# VPAC0_COMMON_0_IVPAC_TOP_0_CFG_SLV_HTS_S_VBUSP register map
Vendor: Texas Instruments
Peripheral module from a debugger description file (folder am62A).
Registers are 32-bit, read-write, reset 0x0 unless marked. A register's access mark holds for its fields unless they carry their own. Offsets are as the file gives them; lines under a group give offsets from that group; [hi:lo] are bit positions; {n}, {i} and the like mark numbered series; 'fields as' and 'values as' point back to an identical list; <NAME> marks a mode.

## VPAC0_COMMON_0_IVPAC_TOP_0_CFG_SLV_HTS_S_VBUSP (part 1 of 4)
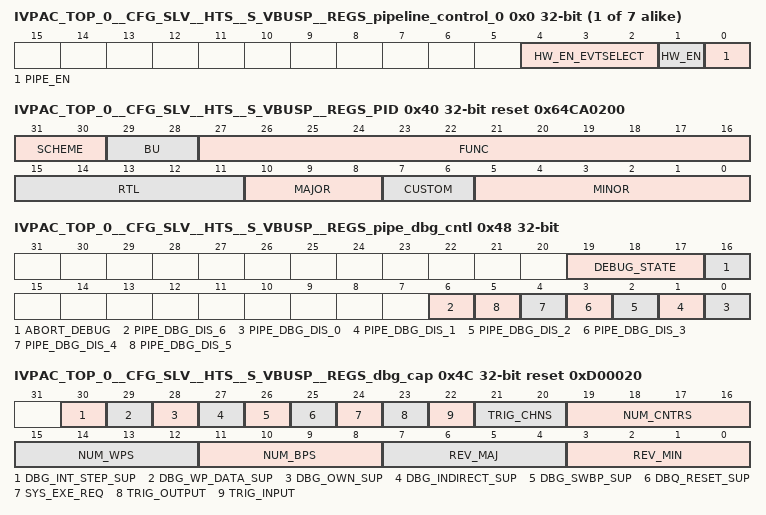
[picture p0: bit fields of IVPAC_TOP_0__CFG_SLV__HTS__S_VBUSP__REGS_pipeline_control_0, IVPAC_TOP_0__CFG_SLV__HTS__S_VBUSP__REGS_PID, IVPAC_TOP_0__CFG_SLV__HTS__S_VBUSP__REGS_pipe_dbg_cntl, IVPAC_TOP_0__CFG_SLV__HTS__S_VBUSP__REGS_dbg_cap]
{0x0+4i} IVPAC_TOP_0__CFG_SLV__HTS__S_VBUSP__REGS_pipeline_control_{i} (i=0..6) — Enable pipeline to activate all connected scheduler
  [4:2] HW_EN_EVTSELECT — Hw triggered pipeline enable on internally generated hts_event[hw_en_evtselect]
  [1] HW_EN — Hw event triggerred Pipeline {i} enable, '1': activate pipeline to receive hw event as described in hw_en_evtselect and hts_event_gen.evt_select , '0' : hw event based pipeline is not enabled
  [0] PIPE_EN — Pipeline {i} enable, writing '1' activate pipeline , writing '0' during active pipeline is illegal and behavior is undefined, read '1' -> pipeline is active , read '0' -> pipeline is inactive
0x40 IVPAC_TOP_0__CFG_SLV__HTS__S_VBUSP__REGS_PID ro reset 0x64CA0200 — HTS PID
  [31:30] SCHEME — Used to distinguish between old scheme and new scheme. Spare bit to encode future schemes
  [29:28] BU — BU indicator DSPS ==> 0x0 WTBU ==> 0x1 Processors ==> 0x2
  [27:16] FUNC — Function indicates a software compatible module family. If there is no level of software compatibility a new FUNC number, and hence PID, should be assigned.
  [15:11] RTL — RTL Version. R as described in PDR with additional clarifications and definitions below. Must be easily ECO-able or controlled during fabrication. Ideally through a top level metal mask or e-fuse. This number is maintained/owned by IP design owner. RTL follows a numbering such as X.Y.R.Z which are explained in this table. R changes ONLY when: (1) PDS uploads occur which may have been due to spec changes (2) Bug fixes occur (3) Resets to '0' when X or Y changes. Design team has an internal 'Z' (customer invisible) number which increments on every drop that happens due to DV and RTL updates. Z resets to 0 when R increments.
  [10:8] MAJOR — Major Revision. X as described in PDR with additional clarifications/definitions below. This number is owned/maintained by IP specification owner. X is part of IP numbering X.Y.R.Z. X changes ONLY when: (1) There is a major feature addition. An example would be adding Master Mode to Utopia Level2. The Func field (or Class/Type in old PID format) will remain the same. X does NOT change due to: (1) Bug fixes (2) Change in feature parameters.
  [7:6] CUSTOM — Indicates a special version for a particular device. Consequence of use may avoid use of standard Chip Support Library (CSL) / Drivers. 0 if non-custom.
  [5:0] MINOR — Minor Revision. Y as described in PDR with additional clarifications/definitions below. This number is owned/maintained by IP specification owner. Y changes ONLY when: (1) Features are scaled (up or down). Flexibility exists in that this feature scalability may either be represented in the Y change or a specific register in the IP that indicates which features are exactly available. (2) When feature creeps from Is-Not list to Is list. But this may not be the case once it sees silicon - in which case X will change. Y does NOT change due to: (1) Bug fixes (2) Typos or clarifications (3) major functional/feature change/addition/deletion. Instead these changes may be reflected via R, S, X as applicable. Spec owner maintains a customer-invisible number 'S' which changes due to: (1) Typos/clarifications (2) Bug documentation. Note that this bug is not due to a spec change but due to implementation. Nevertheless, the spec tracks the IP bugs. An RTL release (say for silicon PG1.1) that occurs due to bug fix should document the corresponding spec number (X.Y.S) in its release notes.
0x48 IVPAC_TOP_0__CFG_SLV__HTS__S_VBUSP__REGS_pipe_dbg_cntl access per field — Pipeline Debug Control register is used by debug software to control pipeline debug behavior
  [19:17] DEBUG_STATE ro — Current state of Debug activity
  [16] ABORT_DEBUG wo — '1' -> Abort Debug activity on debug enabled pipelines, '0' no impact
  [6] PIPE_DBG_DIS_6 rw — '1' -> Pipeline6 doesn't respond to debug events, '0' Pipeline5 respond to debug events
  [n] PIPE_DBG_DIS_{n} rw (n=0..5) — '1' -> Pipeline{n} doesn't respond to debug events, '0' Pipeline{n} respond to debug events
0x4C IVPAC_TOP_0__CFG_SLV__HTS__S_VBUSP__REGS_dbg_cap ro reset 0xD00020 — Debug Capability register is used by debug software to determine which optional debug modules are present and how many instances of each module exist.
  [30] DBG_INT_STEP_SUP — Indicates that debug execution control can determine if single step blocks or allows interrupts. b0 No step/interrupt control b1 Step interrupt control via DBG_INT_STEP_IN
  [29] DBG_WP_DATA_SUP — Indicates if the WP resources has corresponding data qualification. b0 - Not supported. b1 - Data qualifiers are supported.
  [28] DBG_OWN_SUP — Indicates if the HWA supports an module ownership. v2.0 and above. b0 - Not Supported. b1 - Ownership supported.
  [27] DBG_INDIRECT_SUP — Indicates if the HWA supports an indirect memory access port. v2.0 and above. b0 - Not Supported. b1 - Indirect port supported.
  [26] DBG_SWBP_SUP — Whether HWA Core supports SWBP or not. b0 - Not Supported. b1 - Supported.
  [25] DBQ_RESET_SUP — Whether HWA Core reset is supported or not which does not affect debug logic. b0 - Not Supported. b1 - Supported.
  [24] SYS_EXE_REQ — Whether HWA Core Execution status and control is supported. b0 - Not Supported. b1 - Supported.
  [23] TRIG_OUTPUT — b0 - Trigger Outputs are not supported. b1 - Trigger Outputs are supported.
  [22] TRIG_INPUT — b0 - Trigger Inputs are not supported. b1 - Trigger Inputs are supported.
  [21:20] TRIG_CHNS — Number of Trigger Channels Supported. b00 ------ No channels supported. b01 ------ One channel supported. b10 ------ Two channels supported. Others ---- Reserved.
  [19:16] NUM_CNTRS — The number of counter modules that exist. The registers supporting the counter modules must be implemented consecutively in the memory map.
  [15:12] NUM_WPS — The number of watchpoint modules that exist. The registers supporting the watchpoint modules must be implemented consecutively in the memory map
  [11:8] NUM_BPS — The number of breakpoint modules that exist. The registers supporting the breakpoint modules must be implemented consecutively in the memory map.
  [7:4] REV_MAJ — Major Revision
  [3:0] REV_MIN — Minor Revision
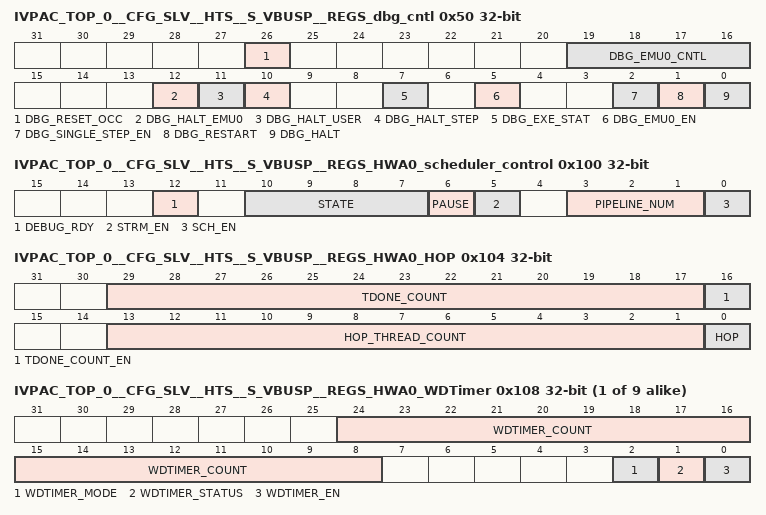
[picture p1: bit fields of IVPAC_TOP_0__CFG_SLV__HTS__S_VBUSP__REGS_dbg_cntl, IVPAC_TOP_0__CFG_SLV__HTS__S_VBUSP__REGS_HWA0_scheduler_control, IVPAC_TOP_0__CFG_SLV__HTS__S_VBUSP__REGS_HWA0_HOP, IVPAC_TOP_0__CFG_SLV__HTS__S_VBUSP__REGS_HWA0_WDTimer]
0x50 IVPAC_TOP_0__CFG_SLV__HTS__S_VBUSP__REGS_dbg_cntl access not given — Debug Control register is used by debug software to control all of the basic debug functions.
  [26] DBG_RESET_OCC — Sticky status bit to reflect reset has been generated (access R/W1TC)
  [19:16] DBG_EMU0_CNTL rw — EMU0 output control. The cross trigger output control. The value in this field determines the behavior of the outputs generated on EMU0. NOTE: The effect of setting any non-zero value is ignored if the HWA Core is currently in HALTED state until the HWA core exits and re-enters HALTED state. DBG_EMUn_CNTL Output Enable Output Pulse Description 0 De-asserted 0 NA No output. Input only 1 Stopping 0 Yes Pulse on halt. If this bit is set when halted then no effect until the HWA re-enters halted state. 2 HWBP 0 Yes Pulse when any HWBP triggers 3 HWWP 0 Yes Pulse when any HWWP triggers 4 Asserted 1 No Drive pin high 5 Asserted 0 No Drive pin low 6-15 - - Reserved
  [12] DBG_HALT_EMU0 ro — Execution halted due to trigger in on EMU0 input Set to '1' when halt due to EMU0 input completes Set to '0' when execution resumes
  [11] DBG_HALT_USER ro — Execution halted due to register update of DBG_HALT Set to '1' when halt due to DBG_HALT update completes Set to '0' when execution resumes
  [10] DBG_HALT_STEP ro — Execution halted due to single step completion Set to '1' when the single step completes Set to '0' when execution resumes
  [7] DBG_EXE_STAT ro — The execution status of the module Set to '1' when halted due to debug event Set to '0' when execution resumes
  [5] DBG_EMU0_EN rw — EMU0 input trigger enable Writing '1' enables halting on the falling edge of the EMU0 input Writing '0' disables halts via EMU0 input
  [2] DBG_SINGLE_STEP_EN rw — Single Step Execution enable. When this bit is set, the accelerator core shall be halted upon execution of a single instruction. This is after the accelerator core has left the halted state by clearing the DBG_HALT control bit. Writing '1' enables halting when the next instruction following exit from halted state is executed. Writing '0' disables halts via single step. NOTE: 1. When the accelerator core enters its natural execution state, it may or may not execute an instruction and re-enter HALTED state.
  [1] DBG_RESTART rw — Debug Restart Status bit.This bit is normally set when the DBG_HALT bit transitions from '1' to '0' when the natural execution state is entered.It is a sticky bit. It may also be set when a synchronous run causes the accelerator to leave halted state. Reading '1' means HWA Core exited halted state (at least temporarily). Reading '0' means HWA Core did not exit halted state. Writing '1' shall clear the bit if set. There is no restriction on when it can be cleared. Writing '0' shall have no effect.
  [0] DBG_HALT rw — Global debug run control. The bit will be read as being set upon entry to HALTED state due to halted state being entered because of SWBP, HWBP, HWWP, EMU0 / 1 trigger or manual halt requested through this control. Writing '1' when read '0' shall cause a halt on the next possible halt boundary.Writing '0' when read '1' returns the system to the natural execution state.A synchronous run hardware request has the same effect.Reading '1' means that the halted state has been reached or been requested by the manual halt mechanism.Reading '0' means that the target is in its natural execution state.NOTE: 1. The natural execution state means the FSM state entered prior to last entry into Halted state. 2. This would be the last application requested FSM state unless the DBG_SYS_EXE_REQ control was used to change it.
{0x54+4i} IVPAC_TOP_0__CFG_SLV__HTS__S_VBUSP__REGS_hts_event_gen{i} (i=0..7) — select one of internal hts_event of width 34 out of 3'b0,pipeline_eop[6:0],1'b0,start_frame_evt,2'b0,hwa_eop[8:0],2'b0,hwa_init[8:0] bus as hts_event{i}
  [5:0] EVT_SELECT — internal hts_event index for hts_event_gen{i}
0x100 IVPAC_TOP_0__CFG_SLV__HTS__S_VBUSP__REGS_HWA0_scheduler_control access per field — Scheduler Control Register
  [12] DEBUG_RDY rw — '0' -> HWA0 Scheduler resources must not be read during halted state. '1'-> HWA0 Scheduler resources are readable during halted state
  [10:7] STATE ro — Current state of HWA0 Scheduler
  [6] PAUSE rw — '1' -> pause/suspend scheduler , '0' -> resume scheduler
  [5] STRM_EN rw — '1' -> Streaming input enable, '0' No streaming input
  [3:1] PIPELINE_NUM rw — Pipeline Number of HWA0 Scheduler
  [0] SCH_EN rw — scheduler enable; write '1' to enable scheduler
0x104 IVPAC_TOP_0__CFG_SLV__HTS__S_VBUSP__REGS_HWA0_HOP access per field — Scheduler HOP Control Register. Help in detecting eop within scheduler. Once configured, it counts task/channel starts and stops issuing further start. Specifically useful for Head of pipe dma scheduler .
  [29:17] TDONE_COUNT ro — current tdone count value
  [16] TDONE_COUNT_EN rw — '1' -> Count tdone(Not impacted due to individual channel mask). Current tdone count available as read value. when enabled, it triggers tdone_intr when (tdone_count==hop_thread_count) '0' -> No count ; Note that tdone_count value is available as read value when hop=1 as well.
  [13:1] HOP_THREAD_COUNT rw — Number of Task count for Head of pipe
  [0] HOP rw — '1' -> Head of Pipe producer Sch , '0' -> No hop
{0x108+0x260*i} IVPAC_TOP_0__CFG_SLV__HTS__S_VBUSP__REGS_HWA{i}_WDTimer access per field (i=0..8) — Watchdog timer control register
  [24:8] WDTIMER_COUNT ro — Current value of HWA{i} Scheduler watchdog timer count
  [2] WDTIMER_MODE rw — Watchdog timeout count '1' -> 128K , '0' -> 64K
  [1] WDTIMER_STATUS ro — HWA{i} Scheduler watchdog timer status '1' -> Timer Active '0' -> Timer Inactive (count is stable)
  [0] WDTIMER_EN rw — '1' -> activate watchdog timer for 64K VPAC/DMPAC cycles between task start and task done '0' -> Disable watchdog timer
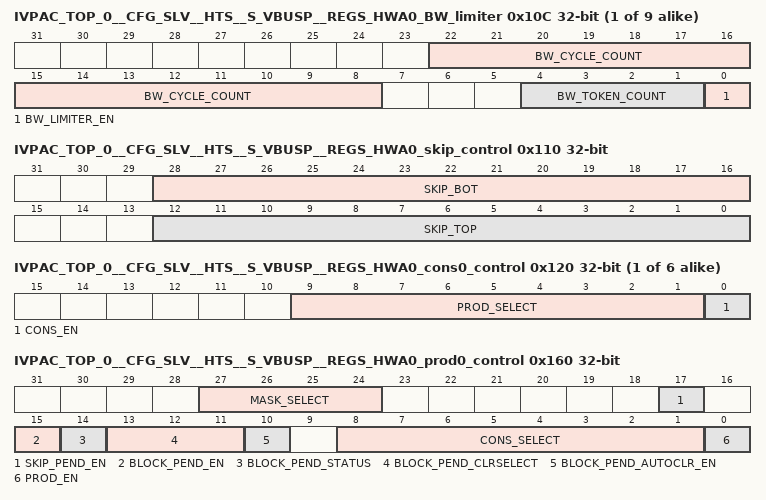
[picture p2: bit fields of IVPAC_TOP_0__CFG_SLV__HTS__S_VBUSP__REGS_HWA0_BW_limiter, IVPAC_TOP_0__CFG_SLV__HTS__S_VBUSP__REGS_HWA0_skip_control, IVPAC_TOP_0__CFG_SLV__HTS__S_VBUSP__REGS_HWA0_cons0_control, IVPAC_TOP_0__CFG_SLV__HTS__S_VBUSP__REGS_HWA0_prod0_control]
{0x10C+0x260*i} IVPAC_TOP_0__CFG_SLV__HTS__S_VBUSP__REGS_HWA{i}_BW_limiter (i=0..8) — Scheduler BW Control Register. Processing unit level BW control. Use DMA to eliminate peak system BW within processing units line/Block
  [22:8] BW_CYCLE_COUNT — Average Cycle count between successive Task Start
  [4:1] BW_TOKEN_COUNT — Max Token count to create average BW
  [0] BW_LIMITER_EN — '1' -> Enable BW limiter function for HWA{i} sch, '0' --> Disable
0x110 IVPAC_TOP_0__CFG_SLV__HTS__S_VBUSP__REGS_HWA0_skip_control — Scheduler Skip Control Register. If enabled in specific prod socket, tdones within skip_top and skip_bot is included in pend generation. tdone_count_en bit in HOP needs to be set to use SKIP feature.
  [28:16] SKIP_BOT — skip/ignore tdone from tdone_count=skip_bot till eop in HWA0 scheduler skip-enabled prod socket
  [12:0] SKIP_TOP — skip/ignore tdone from tdone_count=0 till tdone_count=skip_top value in HWA0 scheduler skip-enabled prod socket
{0x120+8i} IVPAC_TOP_0__CFG_SLV__HTS__S_VBUSP__REGS_HWA0_cons{i}_control (i=0..5) — Controlling consumer socket {i} for HWA0
  [9:1] PROD_SELECT — producer select for HWA0 cons socket {i}
  [0] CONS_EN — '1' -> Consumer socket {i} enable , '0' Disable
0x160 IVPAC_TOP_0__CFG_SLV__HTS__S_VBUSP__REGS_HWA0_prod0_control — Controlling producer socket0 for HWA0
  [27:24] MASK_SELECT — define which tdone_mask apply to prod socket 0. tdone_mask[mask_select] applies to prod_socket0. Valid value in range 0 - 6
  [17] SKIP_PEND_EN — '1' -> Producer socket 0 skip enable , '0' Disable
  [15] BLOCK_PEND_EN — '1' -> block pend at the end of hwa eop enabled at Producer socket 0 , '0' Disable
  [14] BLOCK_PEND_STATUS — '1' -> block pend status at Producer socket 0 , '0' Disable
  [13:11] BLOCK_PEND_CLRSELECT — hts_event_gen[block_pend_clrselect] will be used to clear blocked pend in super pipeline
  [10] BLOCK_PEND_AUTOCLR_EN — '1' -> Enable clearing block pend status at Producer socket 0 by hts_event_gen[block_pend_clrselect], '0' Disable
  [8:1] CONS_SELECT — consumer select for HWA0 prod socket 0. Used in decrementing count of producer buffer
  [0] PROD_EN — '1' -> Producer socket 0 enable , '0' Disable
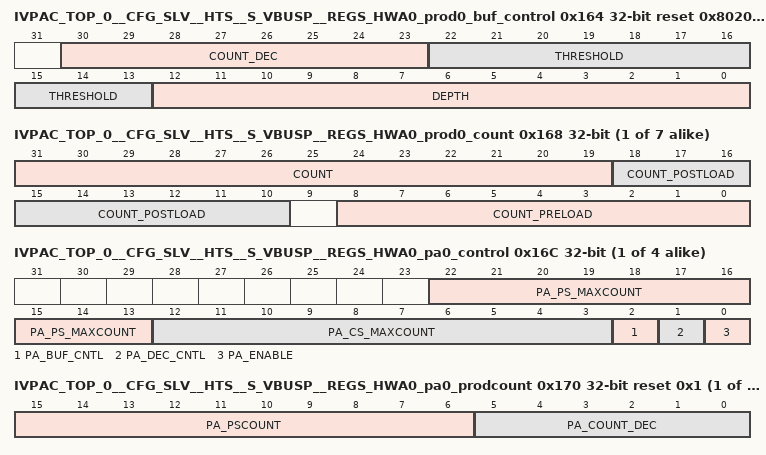
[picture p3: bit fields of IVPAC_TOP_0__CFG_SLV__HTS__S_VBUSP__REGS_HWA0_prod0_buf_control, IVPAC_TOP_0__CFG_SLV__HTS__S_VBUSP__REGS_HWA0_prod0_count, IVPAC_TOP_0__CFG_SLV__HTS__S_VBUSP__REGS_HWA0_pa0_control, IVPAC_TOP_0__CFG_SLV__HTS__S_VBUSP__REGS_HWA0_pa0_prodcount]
{0x164+0x20*i} IVPAC_TOP_0__CFG_SLV__HTS__S_VBUSP__REGS_HWA0_prod{i}_buf_control reset 0x802000 (i=0..6) — Controlling producer socket{i} buffer for HWA0
  [30:23] COUNT_DEC — Count decrement value for prod count
  [22:13] THRESHOLD — Count threshold to generate pend for consumer
  [12:0] DEPTH — Maximum number of producer buffer count
{0x168+0x20*i} IVPAC_TOP_0__CFG_SLV__HTS__S_VBUSP__REGS_HWA0_prod{i}_count access per field (i=0..6) — Defining count values for pre/post load for generating pend by HWA0 prod{i}
  [31:19] COUNT ro — current count value
  [18:10] COUNT_POSTLOAD rw — count postload after producer max thread count reached
  [8:0] COUNT_PRELOAD rw — count preload after scheduler start/init
{0x16C+0x20*i} IVPAC_TOP_0__CFG_SLV__HTS__S_VBUSP__REGS_HWA0_pa{i}_control (i=0..3) — control register to manage pattern adapter on HWA0 prod socket{i}
  [22:13] PA_PS_MAXCOUNT — destination count for pattern adaptation (N), M --> N
  [12:3] PA_CS_MAXCOUNT — source count for pattern adaptation (M), M --> N
  [2] PA_BUF_CNTL — '1' -> Apply threshold, count_preload and count_postload on pattern adapter count (use this only when pa_enable='1') '0' -> Apply threshold, count_preload and count_postload on prod count (same behavior as if no pattern adapter. Note when pa_enable='1' and pa_buf_cntl='0' threshold is not used and ignored)
  [1] PA_DEC_CNTL — '1' -> post pattern adaptation, decrement ps count by count_dec , '0' -> post pattern adaptation, decrement ps count by pa_cs_maxcount
  [0] PA_ENABLE — '1' -> pa enable, '0' -> disable
{0x170+0x20*i} IVPAC_TOP_0__CFG_SLV__HTS__S_VBUSP__REGS_HWA0_pa{i}_prodcount access per field reset 0x1 (i=0..3) — count values for HWA0 prod socket{i}
  [15:6] PA_PSCOUNT ro — current count value of pa prod count
  [5:0] PA_COUNT_DEC rw — Decrement count value of pa_prod_count after pattern adapter prod count reaches threshold
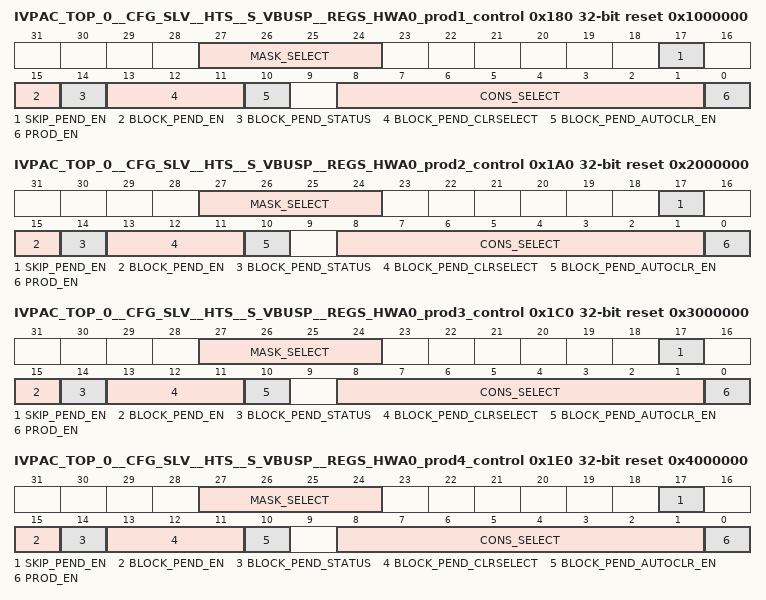
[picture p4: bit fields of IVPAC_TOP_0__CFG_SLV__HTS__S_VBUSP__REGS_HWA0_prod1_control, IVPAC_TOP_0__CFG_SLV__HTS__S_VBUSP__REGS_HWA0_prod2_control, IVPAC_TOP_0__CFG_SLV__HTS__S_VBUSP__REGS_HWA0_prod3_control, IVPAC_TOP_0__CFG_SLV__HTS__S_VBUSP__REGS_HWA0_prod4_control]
0x180 IVPAC_TOP_0__CFG_SLV__HTS__S_VBUSP__REGS_HWA0_prod1_control reset 0x1000000 — Controlling producer socket1 for HWA0
  [27:24] MASK_SELECT — define which tdone_mask apply to prod socket 1. tdone_mask[mask_select] applies to prod_socket1. Valid value in range 0 - 6
  [17] SKIP_PEND_EN — '1' -> Producer socket 1 skip enable , '0' Disable
  [15] BLOCK_PEND_EN — '1' -> block pend at the end of hwa eop enabled at Producer socket 1 , '0' Disable
  [14] BLOCK_PEND_STATUS — '1' -> block pend status at Producer socket 1 , '0' Disable
  [13:11] BLOCK_PEND_CLRSELECT — hts_event_gen[block_pend_clrselect] will be used to clear blocked pend in super pipeline
  [10] BLOCK_PEND_AUTOCLR_EN — '1' -> Enable clearing block pend status at Producer socket 1 by hts_event_gen[block_pend_clrselect], '0' Disable
  [8:1] CONS_SELECT — consumer select for HWA0 prod socket 1. Used in decrementing count of producer buffer
  [0] PROD_EN — '1' -> Producer socket 1 enable , '0' Disable
0x1A0 IVPAC_TOP_0__CFG_SLV__HTS__S_VBUSP__REGS_HWA0_prod2_control reset 0x2000000 — Controlling producer socket2 for HWA0
  [27:24] MASK_SELECT — define which tdone_mask apply to prod socket 2. tdone_mask[mask_select] applies to prod_socket2. Valid value in range 0 - 6
  [17] SKIP_PEND_EN — '1' -> Producer socket 2 skip enable , '0' Disable
  [15] BLOCK_PEND_EN — '1' -> block pend at the end of hwa eop enabled at Producer socket 2 , '0' Disable
  [14] BLOCK_PEND_STATUS — '1' -> block pend status at Producer socket 2 , '0' Disable
  [13:11] BLOCK_PEND_CLRSELECT — hts_event_gen[block_pend_clrselect] will be used to clear blocked pend in super pipeline
  [10] BLOCK_PEND_AUTOCLR_EN — '1' -> Enable clearing block pend status at Producer socket 2 by hts_event_gen[block_pend_clrselect], '0' Disable
  [8:1] CONS_SELECT — consumer select for HWA0 prod socket 2. Used in decrementing count of producer buffer
  [0] PROD_EN — '1' -> Producer socket 2 enable , '0' Disable
0x1C0 IVPAC_TOP_0__CFG_SLV__HTS__S_VBUSP__REGS_HWA0_prod3_control reset 0x3000000 — Controlling producer socket3 for HWA0
  [27:24] MASK_SELECT — define which tdone_mask apply to prod socket 3. tdone_mask[mask_select] applies to prod_socket3. Valid value in range 0 - 6
  [17] SKIP_PEND_EN — '1' -> Producer socket 3 skip enable , '0' Disable
  [15] BLOCK_PEND_EN — '1' -> block pend at the end of hwa eop enabled at Producer socket 3 , '0' Disable
  [14] BLOCK_PEND_STATUS — '1' -> block pend status at Producer socket 3 , '0' Disable
  [13:11] BLOCK_PEND_CLRSELECT — hts_event_gen[block_pend_clrselect] will be used to clear blocked pend in super pipeline
  [10] BLOCK_PEND_AUTOCLR_EN — '1' -> Enable clearing block pend status at Producer socket 3 by hts_event_gen[block_pend_clrselect], '0' Disable
  [8:1] CONS_SELECT — consumer select for HWA0 prod socket 3. Used in decrementing count of producer buffer
  [0] PROD_EN — '1' -> Producer socket 3 enable , '0' Disable
0x1E0 IVPAC_TOP_0__CFG_SLV__HTS__S_VBUSP__REGS_HWA0_prod4_control reset 0x4000000 — Controlling producer socket4 for HWA0
  [27:24] MASK_SELECT — define which tdone_mask apply to prod socket 4. tdone_mask[mask_select] applies to prod_socket4. Valid value in range 0 - 6
  [17] SKIP_PEND_EN — '1' -> Producer socket 4 skip enable , '0' Disable
  [15] BLOCK_PEND_EN — '1' -> block pend at the end of hwa eop enabled at Producer socket 4 , '0' Disable
  [14] BLOCK_PEND_STATUS — '1' -> block pend status at Producer socket 4 , '0' Disable
  [13:11] BLOCK_PEND_CLRSELECT — hts_event_gen[block_pend_clrselect] will be used to clear blocked pend in super pipeline
  [10] BLOCK_PEND_AUTOCLR_EN — '1' -> Enable clearing block pend status at Producer socket 4 by hts_event_gen[block_pend_clrselect], '0' Disable
  [8:1] CONS_SELECT — consumer select for HWA0 prod socket 4. Used in decrementing count of producer buffer
  [0] PROD_EN — '1' -> Producer socket 4 enable , '0' Disable
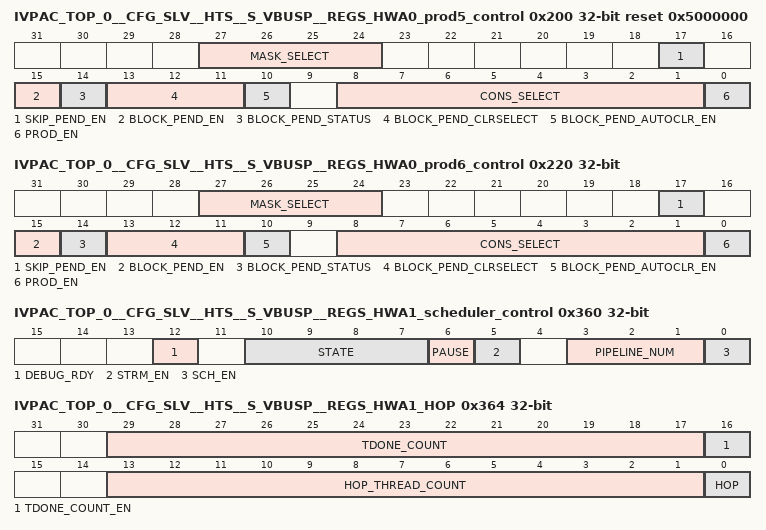
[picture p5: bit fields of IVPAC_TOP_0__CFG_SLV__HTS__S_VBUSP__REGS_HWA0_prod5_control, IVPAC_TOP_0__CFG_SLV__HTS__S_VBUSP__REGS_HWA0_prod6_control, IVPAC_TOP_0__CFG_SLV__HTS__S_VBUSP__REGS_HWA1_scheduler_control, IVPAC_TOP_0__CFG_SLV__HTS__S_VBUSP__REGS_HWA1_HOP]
0x200 IVPAC_TOP_0__CFG_SLV__HTS__S_VBUSP__REGS_HWA0_prod5_control reset 0x5000000 — Controlling producer socket5 for HWA0
  [27:24] MASK_SELECT — define which tdone_mask apply to prod socket 5. tdone_mask[mask_select] applies to prod_socket5. Valid value in range 0 - 6
  [17] SKIP_PEND_EN — '1' -> Producer socket 5 skip enable , '0' Disable
  [15] BLOCK_PEND_EN — '1' -> block pend at the end of hwa eop enabled at Producer socket 5 , '0' Disable
  [14] BLOCK_PEND_STATUS — '1' -> block pend status at Producer socket 5 , '0' Disable
  [13:11] BLOCK_PEND_CLRSELECT — hts_event_gen[block_pend_clrselect] will be used to clear blocked pend in super pipeline
  [10] BLOCK_PEND_AUTOCLR_EN — '1' -> Enable clearing block pend status at Producer socket 5 by hts_event_gen[block_pend_clrselect], '0' Disable
  [8:1] CONS_SELECT — consumer select for HWA0 prod socket 5. Used in decrementing count of producer buffer
  [0] PROD_EN — '1' -> Producer socket 5 enable , '0' Disable
0x220 IVPAC_TOP_0__CFG_SLV__HTS__S_VBUSP__REGS_HWA0_prod6_control — Controlling producer socket6 for HWA0
  [27:24] MASK_SELECT — define which tdone_mask apply to prod socket 6. tdone_mask[mask_select] applies to prod_socket6. Valid value in range 0 - 6
  [17] SKIP_PEND_EN — '1' -> Producer socket 6 skip enable , '0' Disable
  [15] BLOCK_PEND_EN — '1' -> block pend at the end of hwa eop enabled at Producer socket 6 , '0' Disable
  [14] BLOCK_PEND_STATUS — '1' -> block pend status at Producer socket 6 , '0' Disable
  [13:11] BLOCK_PEND_CLRSELECT — hts_event_gen[block_pend_clrselect] will be used to clear blocked pend in super pipeline
  [10] BLOCK_PEND_AUTOCLR_EN — '1' -> Enable clearing block pend status at Producer socket 6 by hts_event_gen[block_pend_clrselect], '0' Disable
  [8:1] CONS_SELECT — consumer select for HWA0 prod socket 6. Used in decrementing count of producer buffer
  [0] PROD_EN — '1' -> Producer socket 6 enable , '0' Disable
0x360 IVPAC_TOP_0__CFG_SLV__HTS__S_VBUSP__REGS_HWA1_scheduler_control access per field — Scheduler Control Register
  [12] DEBUG_RDY rw — '0' -> HWA1 Scheduler resources must not be read during halted state. '1'-> HWA1 Scheduler resources are readable during halted state
  [10:7] STATE ro — Current state of HWA1 Scheduler
  [6] PAUSE rw — '1' -> pause/suspend scheduler , '0' -> resume scheduler
  [5] STRM_EN rw — '1' -> Streaming input enable, '0' No streaming input
  [3:1] PIPELINE_NUM rw — Pipeline Number of HWA1 Scheduler
  [0] SCH_EN rw — scheduler enable; write '1' to enable scheduler
0x364 IVPAC_TOP_0__CFG_SLV__HTS__S_VBUSP__REGS_HWA1_HOP access per field — Scheduler HOP Control Register. Help in detecting eop within scheduler. Once configured, it counts task/channel starts and stops issuing further start. Specifically useful for Head of pipe dma scheduler .
  fields as IVPAC_TOP_0__CFG_SLV__HTS__S_VBUSP__REGS_HWA0_HOP
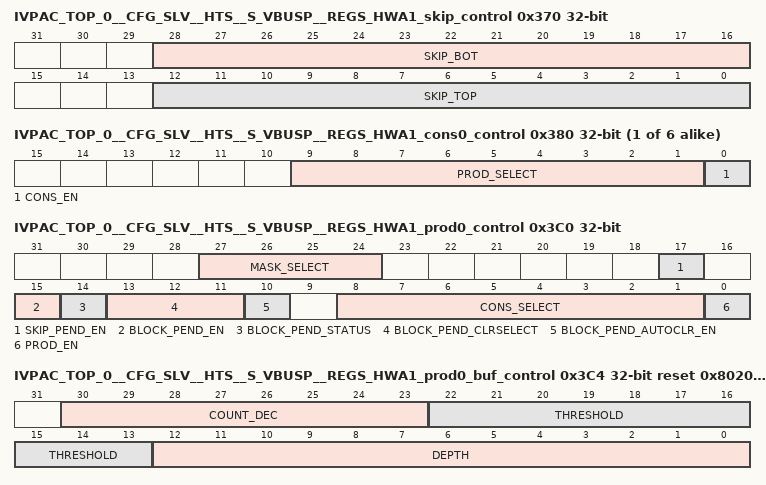
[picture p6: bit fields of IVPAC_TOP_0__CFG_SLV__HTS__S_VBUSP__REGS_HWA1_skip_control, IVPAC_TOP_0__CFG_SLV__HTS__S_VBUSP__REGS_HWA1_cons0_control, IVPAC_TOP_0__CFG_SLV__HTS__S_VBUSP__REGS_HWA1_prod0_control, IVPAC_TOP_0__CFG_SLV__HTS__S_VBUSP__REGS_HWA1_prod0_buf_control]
0x370 IVPAC_TOP_0__CFG_SLV__HTS__S_VBUSP__REGS_HWA1_skip_control — Scheduler Skip Control Register. If enabled in specific prod socket, tdones within skip_top and skip_bot is included in pend generation. tdone_count_en bit in HOP needs to be set to use SKIP feature.
  [28:16] SKIP_BOT — skip/ignore tdone from tdone_count=skip_bot till eop in HWA1 scheduler skip-enabled prod socket
  [12:0] SKIP_TOP — skip/ignore tdone from tdone_count=0 till tdone_count=skip_top value in HWA1 scheduler skip-enabled prod socket
{0x380+8i} IVPAC_TOP_0__CFG_SLV__HTS__S_VBUSP__REGS_HWA1_cons{i}_control (i=0..5) — Controlling consumer socket {i} for HWA1
  [9:1] PROD_SELECT — producer select for HWA1 cons socket {i}
  [0] CONS_EN — '1' -> Consumer socket {i} enable , '0' Disable
0x3C0 IVPAC_TOP_0__CFG_SLV__HTS__S_VBUSP__REGS_HWA1_prod0_control — Controlling producer socket0 for HWA1
  [27:24] MASK_SELECT — define which tdone_mask apply to prod socket 0. tdone_mask[mask_select] applies to prod_socket0. Valid value in range 0 - 6
  [17] SKIP_PEND_EN — '1' -> Producer socket 0 skip enable , '0' Disable
  [15] BLOCK_PEND_EN — '1' -> block pend at the end of hwa eop enabled at Producer socket 0 , '0' Disable
  [14] BLOCK_PEND_STATUS — '1' -> block pend status at Producer socket 0 , '0' Disable
  [13:11] BLOCK_PEND_CLRSELECT — hts_event_gen[block_pend_clrselect] will be used to clear blocked pend in super pipeline
  [10] BLOCK_PEND_AUTOCLR_EN — '1' -> Enable clearing block pend status at Producer socket 0 by hts_event_gen[block_pend_clrselect], '0' Disable
  [8:1] CONS_SELECT — consumer select for HWA1 prod socket 0. Used in decrementing count of producer buffer
  [0] PROD_EN — '1' -> Producer socket 0 enable , '0' Disable
{0x3C4+0x20*i} IVPAC_TOP_0__CFG_SLV__HTS__S_VBUSP__REGS_HWA1_prod{i}_buf_control reset 0x802000 (i=0..6) — Controlling producer socket{i} buffer for HWA1
  fields as IVPAC_TOP_0__CFG_SLV__HTS__S_VBUSP__REGS_HWA0_prod0_buf_control
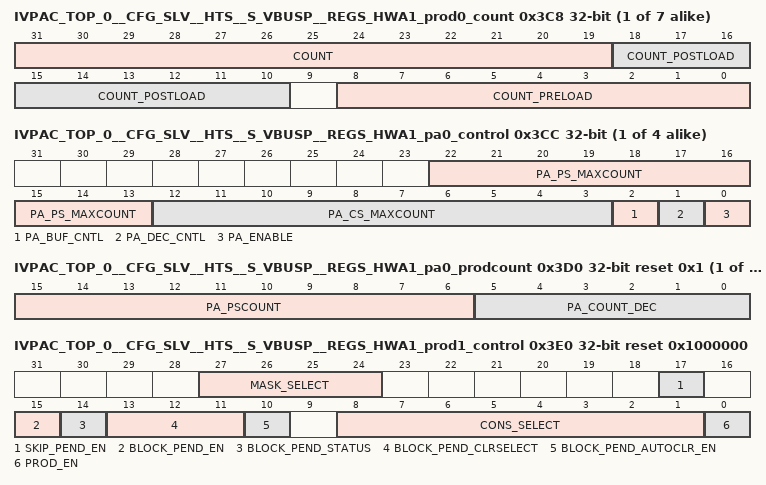
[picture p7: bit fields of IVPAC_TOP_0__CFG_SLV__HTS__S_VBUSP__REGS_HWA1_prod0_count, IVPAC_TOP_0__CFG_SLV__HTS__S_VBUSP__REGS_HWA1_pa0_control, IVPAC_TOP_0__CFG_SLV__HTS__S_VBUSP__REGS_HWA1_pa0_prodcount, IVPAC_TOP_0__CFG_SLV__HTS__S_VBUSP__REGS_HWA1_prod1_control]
{0x3C8+0x20*i} IVPAC_TOP_0__CFG_SLV__HTS__S_VBUSP__REGS_HWA1_prod{i}_count access per field (i=0..6) — Defining count values for pre/post load for generating pend by HWA1 prod{i}
  fields as IVPAC_TOP_0__CFG_SLV__HTS__S_VBUSP__REGS_HWA0_prod0_count
{0x3CC+0x20*i} IVPAC_TOP_0__CFG_SLV__HTS__S_VBUSP__REGS_HWA1_pa{i}_control (i=0..3) — control register to manage pattern adapter on HWA1 prod socket{i}
  fields as IVPAC_TOP_0__CFG_SLV__HTS__S_VBUSP__REGS_HWA0_pa0_control
{0x3D0+0x20*i} IVPAC_TOP_0__CFG_SLV__HTS__S_VBUSP__REGS_HWA1_pa{i}_prodcount access per field reset 0x1 (i=0..3) — count values for HWA1 prod socket{i}
  fields as IVPAC_TOP_0__CFG_SLV__HTS__S_VBUSP__REGS_HWA0_pa0_prodcount
0x3E0 IVPAC_TOP_0__CFG_SLV__HTS__S_VBUSP__REGS_HWA1_prod1_control reset 0x1000000 — Controlling producer socket1 for HWA1
  [27:24] MASK_SELECT — define which tdone_mask apply to prod socket 1. tdone_mask[mask_select] applies to prod_socket1. Valid value in range 0 - 6
  [17] SKIP_PEND_EN — '1' -> Producer socket 1 skip enable , '0' Disable
  [15] BLOCK_PEND_EN — '1' -> block pend at the end of hwa eop enabled at Producer socket 1 , '0' Disable
  [14] BLOCK_PEND_STATUS — '1' -> block pend status at Producer socket 1 , '0' Disable
  [13:11] BLOCK_PEND_CLRSELECT — hts_event_gen[block_pend_clrselect] will be used to clear blocked pend in super pipeline
  [10] BLOCK_PEND_AUTOCLR_EN — '1' -> Enable clearing block pend status at Producer socket 1 by hts_event_gen[block_pend_clrselect], '0' Disable
  [8:1] CONS_SELECT — consumer select for HWA1 prod socket 1. Used in decrementing count of producer buffer
  [0] PROD_EN — '1' -> Producer socket 1 enable , '0' Disable
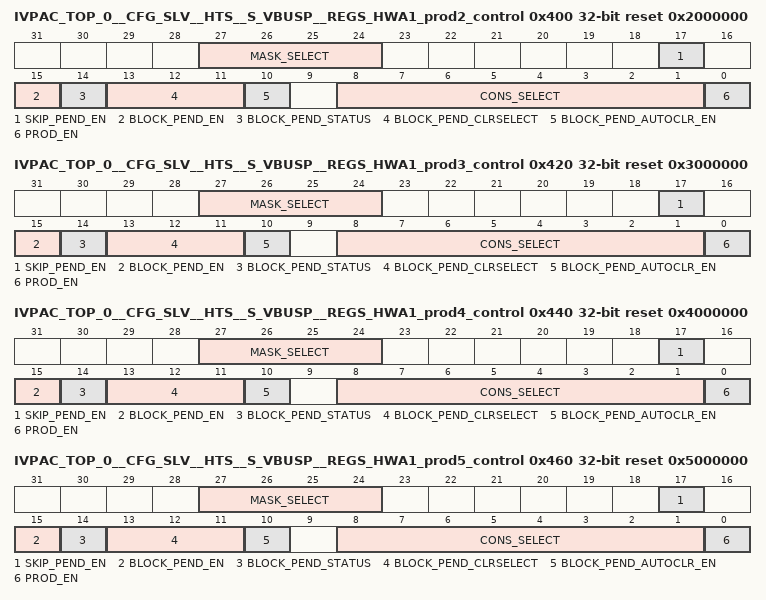
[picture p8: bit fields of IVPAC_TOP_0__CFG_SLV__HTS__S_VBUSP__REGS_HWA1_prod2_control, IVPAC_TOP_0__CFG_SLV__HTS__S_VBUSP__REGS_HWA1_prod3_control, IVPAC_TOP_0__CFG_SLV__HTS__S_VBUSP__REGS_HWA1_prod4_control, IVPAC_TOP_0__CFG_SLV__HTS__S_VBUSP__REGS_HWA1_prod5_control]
0x400 IVPAC_TOP_0__CFG_SLV__HTS__S_VBUSP__REGS_HWA1_prod2_control reset 0x2000000 — Controlling producer socket2 for HWA1
  [27:24] MASK_SELECT — define which tdone_mask apply to prod socket 2. tdone_mask[mask_select] applies to prod_socket2. Valid value in range 0 - 6
  [17] SKIP_PEND_EN — '1' -> Producer socket 2 skip enable , '0' Disable
  [15] BLOCK_PEND_EN — '1' -> block pend at the end of hwa eop enabled at Producer socket 2 , '0' Disable
  [14] BLOCK_PEND_STATUS — '1' -> block pend status at Producer socket 2 , '0' Disable
  [13:11] BLOCK_PEND_CLRSELECT — hts_event_gen[block_pend_clrselect] will be used to clear blocked pend in super pipeline
  [10] BLOCK_PEND_AUTOCLR_EN — '1' -> Enable clearing block pend status at Producer socket 2 by hts_event_gen[block_pend_clrselect], '0' Disable
  [8:1] CONS_SELECT — consumer select for HWA1 prod socket 2. Used in decrementing count of producer buffer
  [0] PROD_EN — '1' -> Producer socket 2 enable , '0' Disable
0x420 IVPAC_TOP_0__CFG_SLV__HTS__S_VBUSP__REGS_HWA1_prod3_control reset 0x3000000 — Controlling producer socket3 for HWA1
  [27:24] MASK_SELECT — define which tdone_mask apply to prod socket 3. tdone_mask[mask_select] applies to prod_socket3. Valid value in range 0 - 6
  [17] SKIP_PEND_EN — '1' -> Producer socket 3 skip enable , '0' Disable
  [15] BLOCK_PEND_EN — '1' -> block pend at the end of hwa eop enabled at Producer socket 3 , '0' Disable
  [14] BLOCK_PEND_STATUS — '1' -> block pend status at Producer socket 3 , '0' Disable
  [13:11] BLOCK_PEND_CLRSELECT — hts_event_gen[block_pend_clrselect] will be used to clear blocked pend in super pipeline
  [10] BLOCK_PEND_AUTOCLR_EN — '1' -> Enable clearing block pend status at Producer socket 3 by hts_event_gen[block_pend_clrselect], '0' Disable
  [8:1] CONS_SELECT — consumer select for HWA1 prod socket 3. Used in decrementing count of producer buffer
  [0] PROD_EN — '1' -> Producer socket 3 enable , '0' Disable
0x440 IVPAC_TOP_0__CFG_SLV__HTS__S_VBUSP__REGS_HWA1_prod4_control reset 0x4000000 — Controlling producer socket4 for HWA1
  [27:24] MASK_SELECT — define which tdone_mask apply to prod socket 4. tdone_mask[mask_select] applies to prod_socket4. Valid value in range 0 - 6
  [17] SKIP_PEND_EN — '1' -> Producer socket 4 skip enable , '0' Disable
  [15] BLOCK_PEND_EN — '1' -> block pend at the end of hwa eop enabled at Producer socket 4 , '0' Disable
  [14] BLOCK_PEND_STATUS — '1' -> block pend status at Producer socket 4 , '0' Disable
  [13:11] BLOCK_PEND_CLRSELECT — hts_event_gen[block_pend_clrselect] will be used to clear blocked pend in super pipeline
  [10] BLOCK_PEND_AUTOCLR_EN — '1' -> Enable clearing block pend status at Producer socket 4 by hts_event_gen[block_pend_clrselect], '0' Disable
  [8:1] CONS_SELECT — consumer select for HWA1 prod socket 4. Used in decrementing count of producer buffer
  [0] PROD_EN — '1' -> Producer socket 4 enable , '0' Disable
0x460 IVPAC_TOP_0__CFG_SLV__HTS__S_VBUSP__REGS_HWA1_prod5_control reset 0x5000000 — Controlling producer socket5 for HWA1
  [27:24] MASK_SELECT — define which tdone_mask apply to prod socket 5. tdone_mask[mask_select] applies to prod_socket5. Valid value in range 0 - 6
  [17] SKIP_PEND_EN — '1' -> Producer socket 5 skip enable , '0' Disable
  [15] BLOCK_PEND_EN — '1' -> block pend at the end of hwa eop enabled at Producer socket 5 , '0' Disable
  [14] BLOCK_PEND_STATUS — '1' -> block pend status at Producer socket 5 , '0' Disable
  [13:11] BLOCK_PEND_CLRSELECT — hts_event_gen[block_pend_clrselect] will be used to clear blocked pend in super pipeline
  [10] BLOCK_PEND_AUTOCLR_EN — '1' -> Enable clearing block pend status at Producer socket 5 by hts_event_gen[block_pend_clrselect], '0' Disable
  [8:1] CONS_SELECT — consumer select for HWA1 prod socket 5. Used in decrementing count of producer buffer
  [0] PROD_EN — '1' -> Producer socket 5 enable , '0' Disable
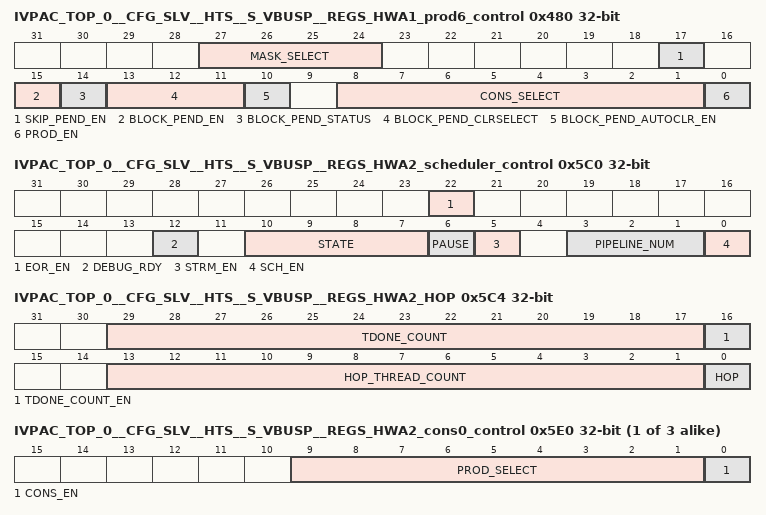
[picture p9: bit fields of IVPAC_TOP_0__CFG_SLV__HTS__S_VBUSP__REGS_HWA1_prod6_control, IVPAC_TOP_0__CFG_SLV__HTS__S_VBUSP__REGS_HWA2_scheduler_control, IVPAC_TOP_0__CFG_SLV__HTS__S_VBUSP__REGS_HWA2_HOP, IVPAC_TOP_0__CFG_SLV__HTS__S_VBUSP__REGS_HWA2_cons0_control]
0x480 IVPAC_TOP_0__CFG_SLV__HTS__S_VBUSP__REGS_HWA1_prod6_control — Controlling producer socket6 for HWA1
  [27:24] MASK_SELECT — define which tdone_mask apply to prod socket 6. tdone_mask[mask_select] applies to prod_socket6. Valid value in range 0 - 6
  [17] SKIP_PEND_EN — '1' -> Producer socket 6 skip enable , '0' Disable
  [15] BLOCK_PEND_EN — '1' -> block pend at the end of hwa eop enabled at Producer socket 6 , '0' Disable
  [14] BLOCK_PEND_STATUS — '1' -> block pend status at Producer socket 6 , '0' Disable
  [13:11] BLOCK_PEND_CLRSELECT — hts_event_gen[block_pend_clrselect] will be used to clear blocked pend in super pipeline
  [10] BLOCK_PEND_AUTOCLR_EN — '1' -> Enable clearing block pend status at Producer socket 6 by hts_event_gen[block_pend_clrselect], '0' Disable
  [8:1] CONS_SELECT — consumer select for HWA1 prod socket 6. Used in decrementing count of producer buffer
  [0] PROD_EN — '1' -> Producer socket 6 enable , '0' Disable
0x5C0 IVPAC_TOP_0__CFG_SLV__HTS__S_VBUSP__REGS_HWA2_scheduler_control access per field — Scheduler Control Register
  [22] EOR_EN rw — '1' -> LDC REGION/sub-frame feature enabled, '0' LDC works in Frame mode only
  [12] DEBUG_RDY rw — '0' -> HWA2 Scheduler resources must not be read during halted state. '1'-> HWA2 Scheduler resources are readable during halted state
  [10:7] STATE ro — Current state of HWA2 Scheduler
  [6] PAUSE rw — '1' -> pause/suspend scheduler , '0' -> resume scheduler
  [5] STRM_EN rw — '1' -> Streaming input enable, '0' No streaming input
  [3:1] PIPELINE_NUM rw — Pipeline Number of HWA2 Scheduler
  [0] SCH_EN rw — scheduler enable; write '1' to enable scheduler
0x5C4 IVPAC_TOP_0__CFG_SLV__HTS__S_VBUSP__REGS_HWA2_HOP access per field — Scheduler HOP Control Register. Help in detecting eop within scheduler. Once configured, it counts task/channel starts and stops issuing further starts. Specifically useful for Head of pipe dma scheduler .
  [29:17] TDONE_COUNT ro — current tdone count value
  [16] TDONE_COUNT_EN rw — '1' -> Count tdone(Not impacted due to individual channel mask). Current tdone count available as read value . when enabled, it triggers tdone_intr when (tdone_count==hop_thread_count) , '0' -> No count
  [13:1] HOP_THREAD_COUNT rw — Number of Task count for Head of pipe
  [0] HOP rw — '1' -> Head of Pipe producer Sch , '0' -> No hop
{0x5E0+8i} IVPAC_TOP_0__CFG_SLV__HTS__S_VBUSP__REGS_HWA2_cons{i}_control (i=0..2) — Controlling consumer socket {i} for HWA2
  [9:1] PROD_SELECT — producer select for HWA2 cons socket {i}
  [0] CONS_EN — '1' -> Consumer socket {i} enable , '0' Disable
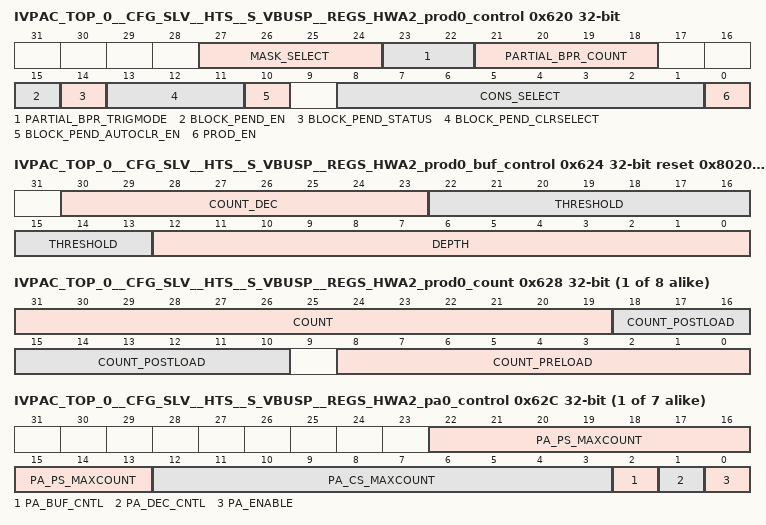
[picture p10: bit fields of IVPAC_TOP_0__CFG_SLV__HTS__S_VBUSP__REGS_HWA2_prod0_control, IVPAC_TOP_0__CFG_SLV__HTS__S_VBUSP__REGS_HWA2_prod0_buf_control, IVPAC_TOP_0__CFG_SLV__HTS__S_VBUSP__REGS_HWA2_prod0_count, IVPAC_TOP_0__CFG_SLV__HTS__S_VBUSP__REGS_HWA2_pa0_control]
0x620 IVPAC_TOP_0__CFG_SLV__HTS__S_VBUSP__REGS_HWA2_prod0_control — Controlling producer socket0 for HWA2
  [27:24] MASK_SELECT — define which tdone_mask apply to prod socket 0. tdone_mask[mask_select] applies to prod_socket0. Valid value in range 0 - 4
  [23:22] PARTIAL_BPR_TRIGMODE — 0: Normal behavior; 1 : Prod Socket 0 is used to trigger DMA channel to transfer end of Row or End of Region Row buffer data for prod socket (0+2)%4. Useful when this Buffer is not completely filled at end of row and it enables triggering separate DMA channel for end of row. Rely on tdone_bpr_early attribute; 2: Prod Socket 0 is used to trigger DMA channel to transfer end of Row or End of Region Row buffer data for prod socket (0+2)%4. Useful when this Buffer is not completely filled at end of row and it enables triggering separate DMA channel for end of row. Rely on end of Row attribute. Must not be used in dual output mode
  [21:18] PARTIAL_BPR_COUNT — Remaining block count to complete configured BPR at End of Row or End of Region Row when LDC is configured in tdone_gen_mode='0'
  [15] BLOCK_PEND_EN — '1' -> block pend at the end of hwa eop enabled at Producer socket 0 , '0' Disable
  [14] BLOCK_PEND_STATUS — '1' -> block pend status at Producer socket 0 , '0' Disable
  [13:11] BLOCK_PEND_CLRSELECT — hts_event_gen[block_pend_clrselect] will be used to clear blocked pend in super pipeline
  [10] BLOCK_PEND_AUTOCLR_EN — '1' -> Enable clearing block pend status at Producer socket 0 by hts_event_gen[block_pend_clrselect], '0' Disable
  [8:1] CONS_SELECT — consumer select for HWA2 prod socket 0. Used in decrementing count of producer buffer
  [0] PROD_EN — '1' -> Producer socket 0 enable , '0' Disable
{0x624+0x20*i} IVPAC_TOP_0__CFG_SLV__HTS__S_VBUSP__REGS_HWA2_prod{i}_buf_control reset 0x802000 (i=0..7) — Controlling producer socket{i} buffer for HWA2
  fields as IVPAC_TOP_0__CFG_SLV__HTS__S_VBUSP__REGS_HWA0_prod0_buf_control
{0x628+0x20*i} IVPAC_TOP_0__CFG_SLV__HTS__S_VBUSP__REGS_HWA2_prod{i}_count access per field (i=0..7) — Defining count values for pre/post load for generating pend by HWA2 prod{i}
  fields as IVPAC_TOP_0__CFG_SLV__HTS__S_VBUSP__REGS_HWA0_prod0_count
{0x62C+0x20*i} IVPAC_TOP_0__CFG_SLV__HTS__S_VBUSP__REGS_HWA2_pa{i}_control (i=0..6) — control register to manage pattern adapter on HWA2 prod socket{i}
  fields as IVPAC_TOP_0__CFG_SLV__HTS__S_VBUSP__REGS_HWA0_pa0_control
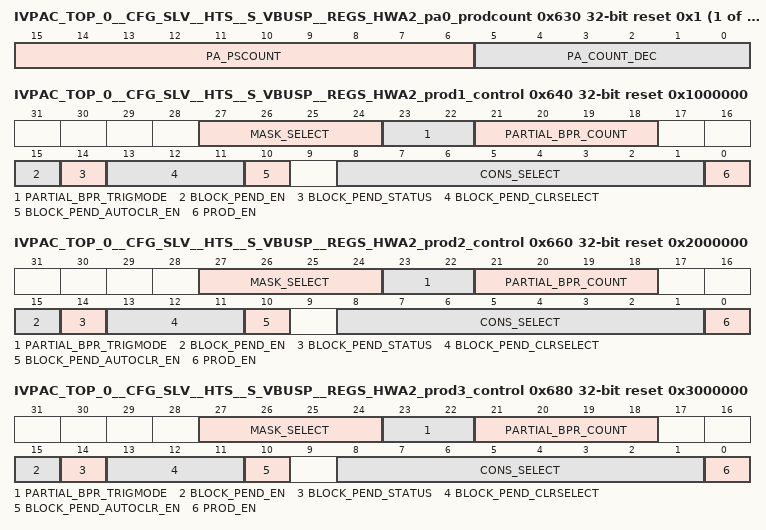
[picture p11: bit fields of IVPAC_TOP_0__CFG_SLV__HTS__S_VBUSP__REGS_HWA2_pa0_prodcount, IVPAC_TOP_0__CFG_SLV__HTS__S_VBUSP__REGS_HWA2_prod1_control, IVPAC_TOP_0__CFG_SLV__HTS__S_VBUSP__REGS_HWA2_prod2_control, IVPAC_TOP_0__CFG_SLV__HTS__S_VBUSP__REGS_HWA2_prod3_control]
{0x630+0x20*i} IVPAC_TOP_0__CFG_SLV__HTS__S_VBUSP__REGS_HWA2_pa{i}_prodcount access per field reset 0x1 (i=0..6) — count values for HWA2 prod socket{i}
  fields as IVPAC_TOP_0__CFG_SLV__HTS__S_VBUSP__REGS_HWA0_pa0_prodcount
0x640 IVPAC_TOP_0__CFG_SLV__HTS__S_VBUSP__REGS_HWA2_prod1_control reset 0x1000000 — Controlling producer socket1 for HWA2
  [27:24] MASK_SELECT — define which tdone_mask apply to prod socket 1. tdone_mask[mask_select] applies to prod_socket1. Valid value in range 0 - 4
  [23:22] PARTIAL_BPR_TRIGMODE — 0: Normal behavior; 1 : Prod Socket 1 is used to trigger DMA channel to transfer end of Row or End of Region Row buffer data for prod socket (1+2)%4. Useful when this Buffer is not completely filled at end of row and it enables triggering separate DMA channel for end of row. Rely on tdone_bpr_early attribute; 2: Prod Socket 1 is used to trigger DMA channel to transfer end of Row or End of Region Row buffer data for prod socket (1+2)%4. Useful when this Buffer is not completely filled at end of row and it enables triggering separate DMA channel for end of row. Rely on end of Row attribute. Must not be used in dual output mode
  [21:18] PARTIAL_BPR_COUNT — Remaining block count to complete configured BPR at End of Row or End of Region Row when LDC is configured in tdone_gen_mode='0'
  [15] BLOCK_PEND_EN — '1' -> block pend at the end of hwa eop enabled at Producer socket 1 , '0' Disable
  [14] BLOCK_PEND_STATUS — '1' -> block pend status at Producer socket 1 , '0' Disable
  [13:11] BLOCK_PEND_CLRSELECT — hts_event_gen[block_pend_clrselect] will be used to clear blocked pend in super pipeline
  [10] BLOCK_PEND_AUTOCLR_EN — '1' -> Enable clearing block pend status at Producer socket 1 by hts_event_gen[block_pend_clrselect], '0' Disable
  [8:1] CONS_SELECT — consumer select for HWA2 prod socket 1. Used in decrementing count of producer buffer
  [0] PROD_EN — '1' -> Producer socket 1 enable , '0' Disable
0x660 IVPAC_TOP_0__CFG_SLV__HTS__S_VBUSP__REGS_HWA2_prod2_control reset 0x2000000 — Controlling producer socket2 for HWA2
  [27:24] MASK_SELECT — define which tdone_mask apply to prod socket 2. tdone_mask[mask_select] applies to prod_socket2. Valid value in range 0 - 4
  [23:22] PARTIAL_BPR_TRIGMODE — 0: Normal behavior; 1 : Prod Socket 2 is used to trigger DMA channel to transfer end of Row or End of Region Row buffer data for prod socket (2+2)%4. Useful when this Buffer is not completely filled at end of row and it enables triggering separate DMA channel for end of row. Rely on tdone_bpr_early attribute; 2: Prod Socket 2 is used to trigger DMA channel to transfer end of Row or End of Region Row buffer data for prod socket (2+2)%4. Useful when this Buffer is not completely filled at end of row and it enables triggering separate DMA channel for end of row. Rely on end of Row attribute. Must not be used in dual output mode
  [21:18] PARTIAL_BPR_COUNT — Remaining block count to complete configured BPR at End of Row or End of Region Row when LDC is configured in tdone_gen_mode='0'
  [15] BLOCK_PEND_EN — '1' -> block pend at the end of hwa eop enabled at Producer socket 2 , '0' Disable
  [14] BLOCK_PEND_STATUS — '1' -> block pend status at Producer socket 2 , '0' Disable
  [13:11] BLOCK_PEND_CLRSELECT — hts_event_gen[block_pend_clrselect] will be used to clear blocked pend in super pipeline
  [10] BLOCK_PEND_AUTOCLR_EN — '1' -> Enable clearing block pend status at Producer socket 2 by hts_event_gen[block_pend_clrselect], '0' Disable
  [8:1] CONS_SELECT — consumer select for HWA2 prod socket 2. Used in decrementing count of producer buffer
  [0] PROD_EN — '1' -> Producer socket 2 enable , '0' Disable
0x680 IVPAC_TOP_0__CFG_SLV__HTS__S_VBUSP__REGS_HWA2_prod3_control reset 0x3000000 — Controlling producer socket3 for HWA2
  [27:24] MASK_SELECT — define which tdone_mask apply to prod socket 3. tdone_mask[mask_select] applies to prod_socket3. Valid value in range 0 - 4
  [23:22] PARTIAL_BPR_TRIGMODE — 0: Normal behavior; 1 : Prod Socket 3 is used to trigger DMA channel to transfer end of Row or End of Region Row buffer data for prod socket (3+2)%4. Useful when this Buffer is not completely filled at end of row and it enables triggering separate DMA channel for end of row. Rely on tdone_bpr_early attribute; 2: Prod Socket 3 is used to trigger DMA channel to transfer end of Row or End of Region Row buffer data for prod socket (3+2)%4. Useful when this Buffer is not completely filled at end of row and it enables triggering separate DMA channel for end of row. Rely on end of Row attribute. Must not be used in dual output mode
  [21:18] PARTIAL_BPR_COUNT — Remaining block count to complete configured BPR at End of Row or End of Region Row when LDC is configured in tdone_gen_mode='0'
  [15] BLOCK_PEND_EN — '1' -> block pend at the end of hwa eop enabled at Producer socket 3 , '0' Disable
  [14] BLOCK_PEND_STATUS — '1' -> block pend status at Producer socket 3 , '0' Disable
  [13:11] BLOCK_PEND_CLRSELECT — hts_event_gen[block_pend_clrselect] will be used to clear blocked pend in super pipeline
  [10] BLOCK_PEND_AUTOCLR_EN — '1' -> Enable clearing block pend status at Producer socket 3 by hts_event_gen[block_pend_clrselect], '0' Disable
  [8:1] CONS_SELECT — consumer select for HWA2 prod socket 3. Used in decrementing count of producer buffer
  [0] PROD_EN — '1' -> Producer socket 3 enable , '0' Disable
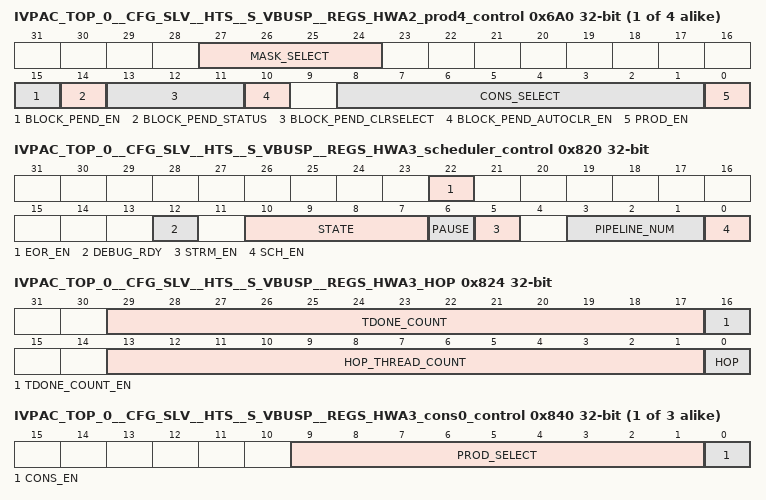
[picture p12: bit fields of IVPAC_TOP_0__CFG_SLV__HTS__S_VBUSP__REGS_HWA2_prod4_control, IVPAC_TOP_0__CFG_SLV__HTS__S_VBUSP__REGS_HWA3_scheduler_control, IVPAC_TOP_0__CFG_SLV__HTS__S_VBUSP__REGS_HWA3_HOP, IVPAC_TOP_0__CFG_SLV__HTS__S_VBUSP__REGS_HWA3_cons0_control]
{0x620+0x20*i} IVPAC_TOP_0__CFG_SLV__HTS__S_VBUSP__REGS_HWA2_prod{i}_control (i=4..7) — Controlling producer socket{i} for HWA2
  [27:24] MASK_SELECT — define which tdone_mask apply to prod socket {i}. tdone_mask[mask_select] applies to prod_socket{i}. Valid value in range 0 - 4
  [15] BLOCK_PEND_EN — '1' -> block pend at the end of hwa eop enabled at Producer socket {i} , '0' Disable
  [14] BLOCK_PEND_STATUS — '1' -> block pend status at Producer socket {i} , '0' Disable
  [13:11] BLOCK_PEND_CLRSELECT — hts_event_gen[block_pend_clrselect] will be used to clear blocked pend in super pipeline
  [10] BLOCK_PEND_AUTOCLR_EN — '1' -> Enable clearing block pend status at Producer socket {i} by hts_event_gen[block_pend_clrselect], '0' Disable
  [8:1] CONS_SELECT — consumer select for HWA2 prod socket {i}. Used in decrementing count of producer buffer
  [0] PROD_EN — '1' -> Producer socket {i} enable , '0' Disable
0x820 IVPAC_TOP_0__CFG_SLV__HTS__S_VBUSP__REGS_HWA3_scheduler_control access per field — Scheduler Control Register
  [22] EOR_EN rw — '1' -> LDC REGION/sub-frame feature enabled, '0' LDC works in Frame mode only
  [12] DEBUG_RDY rw — '0' -> HWA3 Scheduler resources must not be read during halted state. '1'-> HWA3 Scheduler resources are readable during halted state
  [10:7] STATE ro — Current state of HWA3 Scheduler
  [6] PAUSE rw — '1' -> pause/suspend scheduler , '0' -> resume scheduler
  [5] STRM_EN rw — '1' -> Streaming input enable, '0' No streaming input
  [3:1] PIPELINE_NUM rw — Pipeline Number of HWA3 Scheduler
  [0] SCH_EN rw — scheduler enable; write '1' to enable scheduler
0x824 IVPAC_TOP_0__CFG_SLV__HTS__S_VBUSP__REGS_HWA3_HOP access per field — Scheduler HOP Control Register. Help in detecting eop within scheduler. Once configured, it counts task/channel starts and stops issuing further starts. Specifically useful for Head of pipe dma scheduler .
  fields as IVPAC_TOP_0__CFG_SLV__HTS__S_VBUSP__REGS_HWA2_HOP
{0x840+8i} IVPAC_TOP_0__CFG_SLV__HTS__S_VBUSP__REGS_HWA3_cons{i}_control (i=0..2) — Controlling consumer socket {i} for HWA3
  [9:1] PROD_SELECT — producer select for HWA3 cons socket {i}
  [0] CONS_EN — '1' -> Consumer socket {i} enable , '0' Disable
